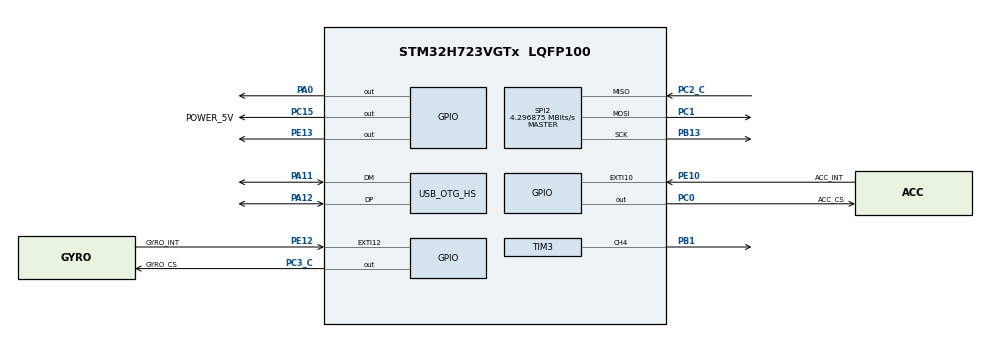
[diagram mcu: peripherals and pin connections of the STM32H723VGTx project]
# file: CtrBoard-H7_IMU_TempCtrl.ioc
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CORTEX_M7.AccessPermission-Cortex_Memory_Protection_Unit_Region0_Settings=MPU_REGION_FULL_ACCESS
CORTEX_M7.BaseAddress-Cortex_Memory_Protection_Unit_Region0_Settings=0x24000000
CORTEX_M7.CPU_DCache=Enabled
CORTEX_M7.CPU_ICache=Enabled
CORTEX_M7.Enable-Cortex_Memory_Protection_Unit_Region0_Settings=MPU_REGION_ENABLE
CORTEX_M7.Enable-Cortex_Memory_Protection_Unit_Region1_Settings=__NULL
CORTEX_M7.IsBufferable-Cortex_Memory_Protection_Unit_Region0_Settings=MPU_ACCESS_BUFFERABLE
CORTEX_M7.IsCacheable-Cortex_Memory_Protection_Unit_Region0_Settings=MPU_ACCESS_CACHEABLE
CORTEX_M7.MPU_Control=MPU_HFNMI_PRIVDEF
CORTEX_M7.Size-Cortex_Memory_Protection_Unit_Region0_Settings=MPU_REGION_SIZE_512KB
CORTEX_M7.TypeExtField-Cortex_Memory_Protection_Unit_Region0_Settings=MPU_TEX_LEVEL1
Dma.Request0=SPI2_RX
Dma.Request1=SPI2_TX
Dma.SPI2_RX.0.Direction=DMA_PERIPH_TO_MEMORY
Dma.SPI2_RX.0.EventEnable=DISABLE
Dma.SPI2_RX.0.FIFOMode=DMA_FIFOMODE_DISABLE
Dma.SPI2_RX.0.Instance=DMA1_Stream0
Dma.SPI2_RX.0.MemDataAlignment=DMA_MDATAALIGN_BYTE
Dma.SPI2_RX.0.MemInc=DMA_MINC_ENABLE
Dma.SPI2_RX.0.Mode=DMA_NORMAL
Dma.SPI2_RX.0.PeriphDataAlignment=DMA_PDATAALIGN_BYTE
Dma.SPI2_RX.0.PeriphInc=DMA_PINC_DISABLE
Dma.SPI2_RX.0.Polarity=HAL_DMAMUX_REQ_GEN_RISING
Dma.SPI2_RX.0.Priority=DMA_PRIORITY_VERY_HIGH
Dma.SPI2_RX.0.RequestNumber=1
Dma.SPI2_RX.0.SignalID=NONE
Dma.SPI2_RX.0.SyncEnable=DISABLE
Dma.SPI2_RX.0.SyncPolarity=HAL_DMAMUX_SYNC_NO_EVENT
Dma.SPI2_RX.0.SyncRequestNumber=1
Dma.SPI2_RX.0.SyncSignalID=NONE
Dma.SPI2_TX.1.Direction=DMA_MEMORY_TO_PERIPH
Dma.SPI2_TX.1.EventEnable=DISABLE
Dma.SPI2_TX.1.FIFOMode=DMA_FIFOMODE_DISABLE
Dma.SPI2_TX.1.Instance=DMA1_Stream1
Dma.SPI2_TX.1.MemDataAlignment=DMA_MDATAALIGN_BYTE
Dma.SPI2_TX.1.MemInc=DMA_MINC_ENABLE
Dma.SPI2_TX.1.Mode=DMA_NORMAL
Dma.SPI2_TX.1.PeriphDataAlignment=DMA_PDATAALIGN_BYTE
Dma.SPI2_TX.1.PeriphInc=DMA_PINC_DISABLE
Dma.SPI2_TX.1.Polarity=HAL_DMAMUX_REQ_GEN_RISING
Dma.SPI2_TX.1.Priority=DMA_PRIORITY_HIGH
Dma.SPI2_TX.1.RequestNumber=1
Dma.SPI2_TX.1.SignalID=NONE
Dma.SPI2_TX.1.SyncEnable=DISABLE
Dma.SPI2_TX.1.SyncPolarity=HAL_DMAMUX_SYNC_NO_EVENT
Dma.SPI2_TX.1.SyncRequestNumber=1
Dma.SPI2_TX.1.SyncSignalID=NONE
FREERTOS.BinarySemaphores01=imuBinarySem01,Static,imuBinarySemControlBlock
FREERTOS.MEMORY_ALLOCATION=1
FREERTOS.Tasks01=defaultTask,24,128,StartDefaultTask,Default,NULL,Static,defaultTaskBuffer,defaultTaskControlBlock;INSTask_rtos,48,4096,IMU_task,As weak,NULL,Static,INSTasklBuffer,INSTaskBlock
Mcu.Family=STM32H7
Mcu.Name=STM32H723VGTx
Mcu.Package=LQFP100
NVIC.DMA1_Stream0_IRQn=true\:6\:0\:true\:false\:true\:true\:false\:true\:true
NVIC.DMA1_Stream1_IRQn=true\:6\:0\:true\:false\:true\:true\:false\:true\:true
NVIC.EXTI15_10_IRQn=true\:6\:0\:true\:false\:true\:true\:true\:true\:true
NVIC.OTG_HS_IRQn=true\:5\:0\:false\:false\:true\:true\:true\:true\:true
NVIC.PriorityGroup=NVIC_PRIORITYGROUP_4
NVIC.SPI2_IRQn=true\:6\:0\:true\:false\:true\:true\:false\:true\:true
NVIC.TIM1_UP_IRQn=true\:15\:0\:false\:false\:true\:false\:false\:true\:true
NVIC.TimeBase=TIM1_UP_IRQn
NVIC.TimeBaseIP=TIM1
PA0.GPIO_Speed=GPIO_SPEED_FREQ_VERY_HIGH
PA0.Signal=GPIO_Output
PA11.Mode=Device_Only_FS
PA11.Signal=USB_OTG_HS_DM
PA12.Mode=Device_Only_FS
PA12.Signal=USB_OTG_HS_DP
PA13(JTMS/SWDIO).Mode=Serial_Wire
PA13(JTMS/SWDIO).Signal=DEBUG_JTMS-SWDIO
PA14(JTCK/SWCLK).Mode=Serial_Wire
PA14(JTCK/SWCLK).Signal=DEBUG_JTCK-SWCLK
PB1.Signal=S_TIM3_CH4
PB13.GPIO_Speed=GPIO_SPEED_FREQ_VERY_HIGH
PB13.Mode=Full_Duplex_Master
PB13.Signal=SPI2_SCK
PC0.GPIO_Label=ACC_CS
PC0.GPIO_Speed=GPIO_SPEED_FREQ_VERY_HIGH
PC0.PinState=GPIO_PIN_SET
PC0.Signal=GPIO_Output
PC1.GPIO_Speed=GPIO_SPEED_FREQ_VERY_HIGH
PC1.Mode=Full_Duplex_Master
PC1.Signal=SPI2_MOSI
PC15-OSC32_OUT.GPIO_Label=POWER_5V
PC15-OSC32_OUT.PinState=GPIO_PIN_SET
PC15-OSC32_OUT.Signal=GPIO_Output
PC2_C.GPIO_Speed=GPIO_SPEED_FREQ_VERY_HIGH
PC2_C.Mode=Full_Duplex_Master
PC2_C.Signal=SPI2_MISO
PC3_C.GPIO_Label=GYRO_CS
PC3_C.GPIO_Speed=GPIO_SPEED_FREQ_VERY_HIGH
PC3_C.PinState=GPIO_PIN_SET
PC3_C.Signal=GPIO_Output
PE10.GPIO_Label=ACC_INT
PE10.Signal=GPXTI10
PE12.GPIO_Label=GYRO_INT
PE12.Signal=GPXTI12
PE13.GPIO_PuPd=GPIO_PULLDOWN
PE13.PinState=GPIO_PIN_RESET
PE13.Signal=GPIO_Output
PH0-OSC_IN.Mode=HSE-External-Oscillator
PH0-OSC_IN.Signal=RCC_OSC_IN
PH1-OSC_OUT.Mode=HSE-External-Oscillator
PH1-OSC_OUT.Signal=RCC_OSC_OUT
ProjectManager.HeapSize=0x1000
ProjectManager.StackSize=0x2000
ProjectManager.TargetToolchain=MDK-ARM V5.27
RCC.ADCFreq_Value=48375000
RCC.APB1Freq_Value=137500000
RCC.APB2Freq_Value=137500000
RCC.APB3Freq_Value=137500000
RCC.APB4Freq_Value=137500000
RCC.CortexFreq_Value=550000000
RCC.D1PPRE=RCC_APB3_DIV2
RCC.D2PPRE1=RCC_APB1_DIV2
RCC.D2PPRE2=RCC_APB2_DIV2
RCC.D3PPRE=RCC_APB4_DIV2
RCC.DIVM1=3
RCC.DIVN1=68
RCC.DIVP1=1
RCC.DIVQ1=4
RCC.HCLKFreq_Value=275000000
RCC.HPRE=RCC_HCLK_DIV2
RCC.HSE_VALUE=24000000
RCC.PLL2FRACN=0
RCC.PLL3FRACN=0
RCC.PLLFRACN=6144
RCC.PLLSourceVirtual=RCC_PLLSOURCE_HSE
RCC.SYSCLKFreq_VALUE=550000000
RCC.SYSCLKSource=RCC_SYSCLKSOURCE_PLLCLK
RCC.USBCLockSelection=RCC_USBCLKSOURCE_HSI48
RCC.USBFreq_Value=48000000
SH.S_TIM3_CH4.0=TIM3_CH4,PWM Generation4 CH4
SPI2.BaudRatePrescaler=SPI_BAUDRATEPRESCALER_32
SPI2.CLKPhase=SPI_PHASE_2EDGE
SPI2.CLKPolarity=SPI_POLARITY_HIGH
SPI2.CalculateBaudRate=4.296875 MBits/s
SPI2.DataSize=SPI_DATASIZE_8BIT
SPI2.Direction=SPI_DIRECTION_2LINES
SPI2.Mode=SPI_MODE_MASTER
SPI2.VirtualType=VM_MASTER
TIM3.AutoReloadPreload=TIM_AUTORELOAD_PRELOAD_ENABLE
TIM3.Channel-PWM\ Generation4\ CH4=TIM_CHANNEL_4
TIM3.Period=10000-1
TIM3.Prescaler=24-1
USB_DEVICE.CLASS_NAME_HS=CDC
USB_DEVICE.VirtualMode=Cdc
USB_DEVICE.VirtualModeHS=Cdc_HS
USB_OTG_HS.VirtualMode-Device_Only_FS=Device_Only_FS
VP_FREERTOS_VS_CMSIS_V2.Mode=CMSIS_V2
VP_SYS_VS_tim1.Mode=TIM1
VP_USB_DEVICE_VS_USB_DEVICE_CDC_HS.Mode=CDC_HS
board=custom

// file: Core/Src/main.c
/* USER CODE BEGIN Header */
/**
  ******************************************************************************
  * @file           : main.c
  * @brief          : Main program body
  ******************************************************************************
  * @attention
  *
  * Copyright (c) 2024 STMicroelectronics.
  * All rights reserved.
  *
  * This software is licensed under terms that can be found in the LICENSE file
  * in the root directory of this software component.
  * If no LICENSE file comes with this software, it is provided AS-IS.
  *
  ******************************************************************************
  */
/* USER CODE END Header */
#include "main.h"
#include "cmsis_os.h"
#include "dma.h"
#include "spi.h"
#include "tim.h"
#include "usb_device.h"
#include "gpio.h"

/* USER CODE BEGIN Includes */
#include "BMI088driver.h"
#include "bsp_dwt.h"
/* USER CODE END Includes */

void SystemClock_Config(void);
static void MPU_Config(void);
void MX_FREERTOS_Init(void);

int main(void)
{

  /* MPU Configuration--------------------------------------------------------*/
  MPU_Config();
/* Enable the CPU Cache */

  /* Enable I-Cache---------------------------------------------------------*/
  SCB_EnableICache();

  /* Enable D-Cache---------------------------------------------------------*/
  SCB_EnableDCache();

  /* MCU Configuration--------------------------------------------------------*/

  /* Reset of all peripherals, Initializes the Flash interface and the Systick. */
  HAL_Init();

  /* Configure the system clock */
  SystemClock_Config();

  /* USER CODE BEGIN SysInit */
  //DWT_Init(480);
  /* USER CODE END SysInit */

  /* Initialize all configured peripherals */
  MX_GPIO_Init();
  MX_DMA_Init();
  MX_SPI2_Init();
  MX_TIM3_Init();

  /* Init scheduler */
  osKernelInitialize();

  /* Call init function for freertos objects (in freertos.c) */
  MX_FREERTOS_Init();

  /* Start scheduler */
  osKernelStart();

  /* We should never get here as control is now taken by the scheduler */
  /* Infinite loop */
  /* USER CODE BEGIN WHILE */
	 MX_USB_DEVICE_Init();
	 DWT_Init(550);//not use
  while (1)
  {
    /* USER CODE END WHILE */

  }
}

void SystemClock_Config(void)
{
  RCC_OscInitTypeDef RCC_OscInitStruct = {0};
  RCC_ClkInitTypeDef RCC_ClkInitStruct = {0};

  /** Supply configuration update enable
  */
  HAL_PWREx_ConfigSupply(PWR_LDO_SUPPLY);

  /** Configure the main internal regulator output voltage
  */
  __HAL_PWR_VOLTAGESCALING_CONFIG(PWR_REGULATOR_VOLTAGE_SCALE0);

  while(!__HAL_PWR_GET_FLAG(PWR_FLAG_VOSRDY)) {}

  /** Initializes the RCC Oscillators according to the specified parameters
  * in the RCC_OscInitTypeDef structure.
  */
  RCC_OscInitStruct.OscillatorType = RCC_OSCILLATORTYPE_HSI48|RCC_OSCILLATORTYPE_HSE;
  RCC_OscInitStruct.HSEState = RCC_HSE_ON;
  RCC_OscInitStruct.HSI48State = RCC_HSI48_ON;
  RCC_OscInitStruct.PLL.PLLState = RCC_PLL_ON;
  RCC_OscInitStruct.PLL.PLLSource = RCC_PLLSOURCE_HSE;
  RCC_OscInitStruct.PLL.PLLM = 3;
  RCC_OscInitStruct.PLL.PLLN = 68;
  RCC_OscInitStruct.PLL.PLLP = 1;
  RCC_OscInitStruct.PLL.PLLQ = 4;
  RCC_OscInitStruct.PLL.PLLR = 2;
  RCC_OscInitStruct.PLL.PLLRGE = RCC_PLL1VCIRANGE_3;
  RCC_OscInitStruct.PLL.PLLVCOSEL = RCC_PLL1VCOWIDE;
  RCC_OscInitStruct.PLL.PLLFRACN = 6144;
  if (HAL_RCC_OscConfig(&RCC_OscInitStruct) != HAL_OK)
  {
    Error_Handler();
  }

  /** Initializes the CPU, AHB and APB buses clocks
  */
  RCC_ClkInitStruct.ClockType = RCC_CLOCKTYPE_HCLK|RCC_CLOCKTYPE_SYSCLK
                              |RCC_CLOCKTYPE_PCLK1|RCC_CLOCKTYPE_PCLK2
                              |RCC_CLOCKTYPE_D3PCLK1|RCC_CLOCKTYPE_D1PCLK1;
  RCC_ClkInitStruct.SYSCLKSource = RCC_SYSCLKSOURCE_PLLCLK;
  RCC_ClkInitStruct.SYSCLKDivider = RCC_SYSCLK_DIV1;
  RCC_ClkInitStruct.AHBCLKDivider = RCC_HCLK_DIV2;
  RCC_ClkInitStruct.APB3CLKDivider = RCC_APB3_DIV2;
  RCC_ClkInitStruct.APB1CLKDivider = RCC_APB1_DIV2;
  RCC_ClkInitStruct.APB2CLKDivider = RCC_APB2_DIV2;
  RCC_ClkInitStruct.APB4CLKDivider = RCC_APB4_DIV2;

  if (HAL_RCC_ClockConfig(&RCC_ClkInitStruct, FLASH_LATENCY_3) != HAL_OK)
  {
    Error_Handler();
  }
}

/* MPU Configuration */

void MPU_Config(void)
{
  MPU_Region_InitTypeDef MPU_InitStruct = {0};

  /* Disables the MPU */
  HAL_MPU_Disable();

  /** Initializes and configures the Region and the memory to be protected
  */
  MPU_InitStruct.Enable = MPU_REGION_ENABLE;
  MPU_InitStruct.Number = MPU_REGION_NUMBER0;
  MPU_InitStruct.BaseAddress = 0x24000000;
  MPU_InitStruct.Size = MPU_REGION_SIZE_512KB;
  MPU_InitStruct.SubRegionDisable = 0x0;
  MPU_InitStruct.TypeExtField = MPU_TEX_LEVEL1;
  MPU_InitStruct.AccessPermission = MPU_REGION_FULL_ACCESS;
  MPU_InitStruct.DisableExec = MPU_INSTRUCTION_ACCESS_ENABLE;
  MPU_InitStruct.IsShareable = MPU_ACCESS_NOT_SHAREABLE;
  MPU_InitStruct.IsCacheable = MPU_ACCESS_CACHEABLE;
  MPU_InitStruct.IsBufferable = MPU_ACCESS_BUFFERABLE;

  HAL_MPU_ConfigRegion(&MPU_InitStruct);
  /* Enables the MPU */
  HAL_MPU_Enable(MPU_HFNMI_PRIVDEF);

}

void HAL_TIM_PeriodElapsedCallback(TIM_HandleTypeDef *htim)
{
  if (htim->Instance == TIM1) {
    HAL_IncTick();
  }
}

void Error_Handler(void)
{
  __disable_irq();
  while (1)
  {
  }
}

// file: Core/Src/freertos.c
/* USER CODE BEGIN Header */
/**
  ******************************************************************************
  * File Name          : freertos.c
  * Description        : Code for freertos applications
  ******************************************************************************
  * @attention
  *
  * Copyright (c) 2024 STMicroelectronics.
  * All rights reserved.
  *
  * This software is licensed under terms that can be found in the LICENSE file
  * in the root directory of this software component.
  * If no LICENSE file comes with this software, it is provided AS-IS.
  *
  ******************************************************************************
  */
/* USER CODE END Header */

#include "FreeRTOS.h"
#include "task.h"
#include "main.h"
#include "cmsis_os.h"

/* USER CODE BEGIN Includes */
#include "imu_temp_ctrl.h"
#include "algorithm.h"
/* USER CODE END Includes */

typedef StaticTask_t osStaticThreadDef_t;
typedef StaticSemaphore_t osStaticSemaphoreDef_t;

/* Definitions for defaultTask */
osThreadId_t defaultTaskHandle;
uint32_t defaultTaskBuffer[ 128 ];
osStaticThreadDef_t defaultTaskControlBlock;
const osThreadAttr_t defaultTask_attributes = {
  .name = "defaultTask",
  .cb_mem = &defaultTaskControlBlock,
  .cb_size = sizeof(defaultTaskControlBlock),
  .stack_mem = &defaultTaskBuffer[0],
  .stack_size = sizeof(defaultTaskBuffer),
  .priority = (osPriority_t) osPriorityNormal,
};
/* Definitions for INSTask_rtos */
osThreadId_t INSTask_rtosHandle;
uint32_t INSTasklBuffer[ 4096 ];
osStaticThreadDef_t INSTaskBlock;
const osThreadAttr_t INSTask_rtos_attributes = {
  .name = "INSTask_rtos",
  .cb_mem = &INSTaskBlock,
  .cb_size = sizeof(INSTaskBlock),
  .stack_mem = &INSTasklBuffer[0],
  .stack_size = sizeof(INSTasklBuffer),
  .priority = (osPriority_t) osPriorityRealtime,
};
/* Definitions for imuBinarySem01 */
osSemaphoreId_t imuBinarySem01Handle;
osStaticSemaphoreDef_t imuBinarySemControlBlock;
const osSemaphoreAttr_t imuBinarySem01_attributes = {
  .name = "imuBinarySem01",
  .cb_mem = &imuBinarySemControlBlock,
  .cb_size = sizeof(imuBinarySemControlBlock),
};

void StartDefaultTask(void *argument);
void IMU_task(void *argument);

extern void MX_USB_DEVICE_Init(void);
void MX_FREERTOS_Init(void); /* (MISRA C 2004 rule 8.1) */

void MX_FREERTOS_Init(void) {

  /* Create the semaphores(s) */
  /* creation of imuBinarySem01 */
  imuBinarySem01Handle = osSemaphoreNew(1, 0, &imuBinarySem01_attributes);

  /* Create the thread(s) */
  /* creation of defaultTask */
  defaultTaskHandle = osThreadNew(StartDefaultTask, NULL, &defaultTask_attributes);

  /* creation of INSTask_rtos */
  INSTask_rtosHandle = osThreadNew(IMU_task, NULL, &INSTask_rtos_attributes);

}

void StartDefaultTask(void *argument)
{
  /* init code for USB_DEVICE */
  MX_USB_DEVICE_Init();
  /* USER CODE BEGIN StartDefaultTask */
  /* Infinite loop */
  for(;;)
  {
		vofa_start();
    osDelay(1);
  }
  /* USER CODE END StartDefaultTask */
}

__weak void IMU_task(void *argument)
{
  for(;;)
  {
    osDelay(1);
  }
}
